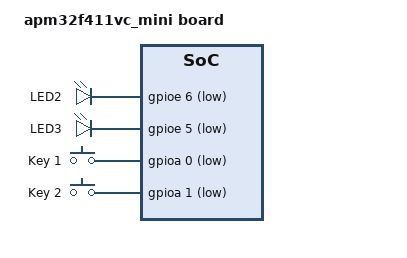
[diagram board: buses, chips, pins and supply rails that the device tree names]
/*
 * apm32f411vc_mini
 *
 * Copyright (c) 2023, Quincy.W <wangqyfm@foxmail.com>
 * SPDX-License-Identifier: Apache-2.0
 */

/dts-v1/;
#include <geehy/f4/apm32f411Xe.dtsi>

/ {
	model = "apm32f411vc_mini board";
	compatible = "geeny,apm32f411";

	chosen {
		zephyr,console = &usart1;
		zephyr,shell-uart = &usart1;
		zephyr,sram = &sram0;
		zephyr,flash = &flash0;
	};

	leds {
		compatible = "gpio-leds";
		yellow_led: led_1 {
			gpios = <&gpioe 6 GPIO_ACTIVE_LOW>;
			label = "LED2";
		};
		red_led: led_2 {
			gpios = <&gpioe 5 GPIO_ACTIVE_LOW>;
			label = "LED3";
		};
	};

	gpio_keys {
		compatible = "gpio-keys";
		user_button_1: button_1 {
			label = "Key 1";
			gpios = <&gpioa 0 GPIO_ACTIVE_LOW>;
		};
		user_button_2: button_2 {
			label = "Key 2";
			gpios = <&gpioa 1 GPIO_ACTIVE_LOW>;
		};
	};

	aliases {
		led0 = &red_led;
		led1 = &yellow_led;
		sw0 = &user_button_1;
		sw1 = &user_button_2;
	};
};

&gpioa {
	status = "okay";
};

&gpioe {
	status = "okay";
};
